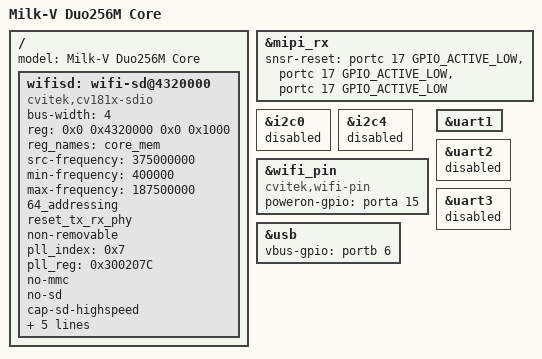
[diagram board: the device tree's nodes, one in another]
/dts-v1/;
#include "cv181x_base_riscv.dtsi"
#include "cv181x_asic_qfn.dtsi"
#include "cv181x_asic_sd.dtsi"
#include "cv181x_default_memmap.dtsi"

/ {
	model = "Milk-V Duo256M Core";

	wifisd: wifi-sd@4320000 {
		compatible = "cvitek,cv181x-sdio";
		bus-width = <4>;
		reg = <0x0 0x4320000 0x0 0x1000>;
		reg_names = "core_mem";
		src-frequency = <375000000>;
		min-frequency = <400000>;
		max-frequency = <187500000>;
		64_addressing;
		reset_tx_rx_phy;
		non-removable;
		pll_index = <0x7>;
		pll_reg = <0x300207C>;
		no-mmc;
		no-sd;
		cap-sd-highspeed;
		sd-uhs-sdr25;
		sd-uhs-ddr50;
		sd-uhs-sdr104;
		interrupt-parent = <&plic0>;
		interrupts = <38 IRQ_TYPE_LEVEL_HIGH>;
		status = "okay";
	};
};

&mipi_rx {
	snsr-reset = <&portc 17 GPIO_ACTIVE_LOW>, <&portc 17 GPIO_ACTIVE_LOW>, <&portc 17 GPIO_ACTIVE_LOW>;
};

&i2c0 {
	status = "disabled";
};

&i2c4 {
	status = "disabled";
};

&wifi_pin {
	status = "okay";
	compatible = "cvitek,wifi-pin";
	poweron-gpio = <&porta 15 GPIO_ACTIVE_HIGH>;
	//wakeup-gpio = <&porta 28 GPIO_ACTIVE_HIGH>;
};

&usb {
	vbus-gpio = <&portb 6 0>;
};

&uart1 {
	status = "okay";
};

&uart2 {
	status = "disabled";
};

&uart3 {
	status = "disabled";
};

